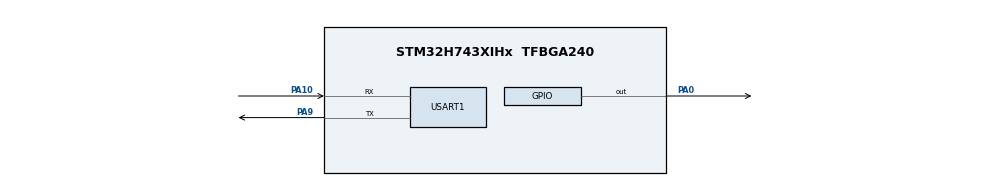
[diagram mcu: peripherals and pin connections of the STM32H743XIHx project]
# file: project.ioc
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CORTEX_M7.CPU_DCache=Enabled
CORTEX_M7.CPU_ICache=Enabled
Dma.Request0=USART1_RX
Dma.USART1_RX.0.Direction=DMA_PERIPH_TO_MEMORY
Dma.USART1_RX.0.EventEnable=DISABLE
Dma.USART1_RX.0.FIFOMode=DMA_FIFOMODE_DISABLE
Dma.USART1_RX.0.Instance=DMA1_Stream0
Dma.USART1_RX.0.MemDataAlignment=DMA_MDATAALIGN_BYTE
Dma.USART1_RX.0.MemInc=DMA_MINC_ENABLE
Dma.USART1_RX.0.Mode=DMA_CIRCULAR
Dma.USART1_RX.0.PeriphDataAlignment=DMA_PDATAALIGN_BYTE
Dma.USART1_RX.0.PeriphInc=DMA_PINC_DISABLE
Dma.USART1_RX.0.Polarity=HAL_DMAMUX_REQ_GEN_RISING
Dma.USART1_RX.0.Priority=DMA_PRIORITY_LOW
Dma.USART1_RX.0.RequestNumber=1
Dma.USART1_RX.0.SignalID=NONE
Dma.USART1_RX.0.SyncEnable=DISABLE
Dma.USART1_RX.0.SyncPolarity=HAL_DMAMUX_SYNC_NO_EVENT
Dma.USART1_RX.0.SyncRequestNumber=1
Dma.USART1_RX.0.SyncSignalID=NONE
Mcu.Family=STM32H7
Mcu.Name=STM32H743XIHx
Mcu.Package=TFBGA240
NVIC.DMA1_Stream0_IRQn=true\:0\:0\:false\:false\:true\:false\:true
NVIC.PriorityGroup=NVIC_PRIORITYGROUP_4
NVIC.USART1_IRQn=true\:0\:0\:false\:false\:true\:true\:true
PA0.Signal=GPIO_Output
PA10.Mode=Asynchronous
PA10.Signal=USART1_RX
PA13\ (JTMS/SWDIO).Mode=Serial_Wire
PA13\ (JTMS/SWDIO).Signal=DEBUG_JTMS-SWDIO
PA14\ (JTCK/SWCLK).Mode=Serial_Wire
PA14\ (JTCK/SWCLK).Signal=DEBUG_JTCK-SWCLK
PA9.Mode=Asynchronous
PA9.Signal=USART1_TX
PC14-OSC32_IN\ (OSC32_IN).Mode=LSE-External-Oscillator
PC14-OSC32_IN\ (OSC32_IN).Signal=RCC_OSC32_IN
PC15-OSC32_OUT\ (OSC32_OUT).Mode=LSE-External-Oscillator
PC15-OSC32_OUT\ (OSC32_OUT).Signal=RCC_OSC32_OUT
PH0-OSC_IN\ (PH0).Mode=HSE-External-Oscillator
PH0-OSC_IN\ (PH0).Signal=RCC_OSC_IN
PH1-OSC_OUT\ (PH1).Mode=HSE-External-Oscillator
PH1-OSC_OUT\ (PH1).Signal=RCC_OSC_OUT
ProjectManager.HeapSize=0x200
ProjectManager.StackSize=0x400
ProjectManager.TargetToolchain=MDK-ARM V5
RCC.ADCFreq_Value=400000000
RCC.APB1Freq_Value=100000000
RCC.APB2Freq_Value=100000000
RCC.APB3Freq_Value=100000000
RCC.APB4Freq_Value=100000000
RCC.CortexFreq_Value=400000000
RCC.D1PPRE=RCC_APB3_DIV2
RCC.D2PPRE1=RCC_APB1_DIV2
RCC.D2PPRE2=RCC_APB2_DIV2
RCC.D3PPRE=RCC_APB4_DIV2
RCC.DIVM1=5
RCC.DIVM2=5
RCC.DIVM3=5
RCC.DIVN1=160
RCC.DIVN2=160
RCC.DIVN3=160
RCC.HCLKFreq_Value=200000000
RCC.HPRE=RCC_HCLK_DIV2
RCC.HSE_Timout=500
RCC.PLL2FRACN=0
RCC.PLL3FRACN=0
RCC.PLLFRACN=0
RCC.PLLSourceVirtual=RCC_PLLSOURCE_HSE
RCC.SYSCLKFreq_VALUE=400000000
RCC.SYSCLKSource=RCC_SYSCLKSOURCE_PLLCLK
RCC.USBFreq_Value=400000000
USART1.VirtualMode-Asynchronous=VM_ASYNC
board=custom

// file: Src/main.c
/* USER CODE BEGIN Header */
/**
  ******************************************************************************
  * @file           : main.c
  * @brief          : Main program body
  ******************************************************************************
  * @attention
  *
  * <h2><center>&copy; Copyright (c) 2020 STMicroelectronics.
  * All rights reserved.</center></h2>
  *
  * This software component is licensed by ST under BSD 3-Clause license,
  * the "License"; You may not use this file except in compliance with the
  * License. You may obtain a copy of the License at:
  *                        opensource.org/licenses/BSD-3-Clause
  *
  ******************************************************************************
  */
/* USER CODE END Header */
#include "main.h"

/* USER CODE BEGIN Includes */
#include "shell_port.h"
#include <stdio.h>
/* USER CODE END Includes */

/* USER CODE BEGIN PM */

int fputc(int ch, FILE* stream)
{
	/* 堵塞判断串口是否发送完成 */
	while ((USART1->ISR & 0X40) == 0);

	/* 串口发送完成，将该字符发送 */
	USART1->TDR = (uint8_t)ch;

	return ch;
}
/* USER CODE END PM */

UART_HandleTypeDef huart1;
DMA_HandleTypeDef hdma_usart1_rx;

/* USER CODE BEGIN PV */
uint8_t recv_buf = 0;
/* USER CODE END PV */

void SystemClock_Config(void);
static void MX_GPIO_Init(void);
static void MX_DMA_Init(void);
static void MX_USART1_UART_Init(void);

/* USER CODE BEGIN 0 */
int test2(int i1, int i2, int i3, int i4, int i5, int i6, int i7, int i8)
{
    printf("input int: %d, %d, %d, %d, %d, %d, %d, %d\r\n", i1, i2, i3, i4, i5, i6, i7, i8);
    return 0;
}
//导出到命令列表里
SHELL_EXPORT_CMD(SHELL_CMD_PERMISSION(0)|SHELL_CMD_TYPE(SHELL_TYPE_CMD_FUNC), test2, test2, test2);

/* USER CODE END 0 */

int main(void)
{

  /* Enable I-Cache---------------------------------------------------------*/
  SCB_EnableICache();

  /* Enable D-Cache---------------------------------------------------------*/
  SCB_EnableDCache();

  /* MCU Configuration--------------------------------------------------------*/

  /* Reset of all peripherals, Initializes the Flash interface and the Systick. */
  HAL_Init();

  /* Configure the system clock */
  SystemClock_Config();

  /* Initialize all configured peripherals */
  MX_GPIO_Init();
  MX_DMA_Init();
  MX_USART1_UART_Init();
  /* USER CODE BEGIN 2 */
    HAL_UART_Receive_IT(&huart1, (uint8_t*)&recv_buf, 1);
    User_Shell_Init();
  /* USER CODE END 2 */

  /* Infinite loop */
  while (1)
  {

  }
}

void SystemClock_Config(void)
{
  RCC_OscInitTypeDef RCC_OscInitStruct = {0};
  RCC_ClkInitTypeDef RCC_ClkInitStruct = {0};
  RCC_PeriphCLKInitTypeDef PeriphClkInitStruct = {0};

  /** Supply configuration update enable
  */
  HAL_PWREx_ConfigSupply(PWR_LDO_SUPPLY);
  /** Configure the main internal regulator output voltage
  */
  __HAL_PWR_VOLTAGESCALING_CONFIG(PWR_REGULATOR_VOLTAGE_SCALE1);

  while(!__HAL_PWR_GET_FLAG(PWR_FLAG_VOSRDY)) {}
  /** Initializes the RCC Oscillators according to the specified parameters
  * in the RCC_OscInitTypeDef structure.
  */
  RCC_OscInitStruct.OscillatorType = RCC_OSCILLATORTYPE_HSE;
  RCC_OscInitStruct.HSEState = RCC_HSE_ON;
  RCC_OscInitStruct.PLL.PLLState = RCC_PLL_ON;
  RCC_OscInitStruct.PLL.PLLSource = RCC_PLLSOURCE_HSE;
  RCC_OscInitStruct.PLL.PLLM = 5;
  RCC_OscInitStruct.PLL.PLLN = 160;
  RCC_OscInitStruct.PLL.PLLP = 2;
  RCC_OscInitStruct.PLL.PLLQ = 2;
  RCC_OscInitStruct.PLL.PLLR = 2;
  RCC_OscInitStruct.PLL.PLLRGE = RCC_PLL1VCIRANGE_2;
  RCC_OscInitStruct.PLL.PLLVCOSEL = RCC_PLL1VCOWIDE;
  RCC_OscInitStruct.PLL.PLLFRACN = 0;
  if (HAL_RCC_OscConfig(&RCC_OscInitStruct) != HAL_OK)
  {
    Error_Handler();
  }
  /** Initializes the CPU, AHB and APB buses clocks
  */
  RCC_ClkInitStruct.ClockType = RCC_CLOCKTYPE_HCLK|RCC_CLOCKTYPE_SYSCLK
                              |RCC_CLOCKTYPE_PCLK1|RCC_CLOCKTYPE_PCLK2
                              |RCC_CLOCKTYPE_D3PCLK1|RCC_CLOCKTYPE_D1PCLK1;
  RCC_ClkInitStruct.SYSCLKSource = RCC_SYSCLKSOURCE_PLLCLK;
  RCC_ClkInitStruct.SYSCLKDivider = RCC_SYSCLK_DIV1;
  RCC_ClkInitStruct.AHBCLKDivider = RCC_HCLK_DIV2;
  RCC_ClkInitStruct.APB3CLKDivider = RCC_APB3_DIV2;
  RCC_ClkInitStruct.APB1CLKDivider = RCC_APB1_DIV2;
  RCC_ClkInitStruct.APB2CLKDivider = RCC_APB2_DIV2;
  RCC_ClkInitStruct.APB4CLKDivider = RCC_APB4_DIV2;

  if (HAL_RCC_ClockConfig(&RCC_ClkInitStruct, FLASH_LATENCY_2) != HAL_OK)
  {
    Error_Handler();
  }
  PeriphClkInitStruct.PeriphClockSelection = RCC_PERIPHCLK_USART1;
  PeriphClkInitStruct.Usart16ClockSelection = RCC_USART16CLKSOURCE_D2PCLK2;
  if (HAL_RCCEx_PeriphCLKConfig(&PeriphClkInitStruct) != HAL_OK)
  {
    Error_Handler();
  }
}

static void MX_USART1_UART_Init(void)
{

  huart1.Instance = USART1;
  huart1.Init.BaudRate = 115200;
  huart1.Init.WordLength = UART_WORDLENGTH_8B;
  huart1.Init.StopBits = UART_STOPBITS_1;
  huart1.Init.Parity = UART_PARITY_NONE;
  huart1.Init.Mode = UART_MODE_TX_RX;
  huart1.Init.HwFlowCtl = UART_HWCONTROL_NONE;
  huart1.Init.OverSampling = UART_OVERSAMPLING_16;
  huart1.Init.OneBitSampling = UART_ONE_BIT_SAMPLE_DISABLE;
  huart1.Init.ClockPrescaler = UART_PRESCALER_DIV1;
  huart1.AdvancedInit.AdvFeatureInit = UART_ADVFEATURE_NO_INIT;
  if (HAL_UART_Init(&huart1) != HAL_OK)
  {
    Error_Handler();
  }
  if (HAL_UARTEx_SetTxFifoThreshold(&huart1, UART_TXFIFO_THRESHOLD_1_8) != HAL_OK)
  {
    Error_Handler();
  }
  if (HAL_UARTEx_SetRxFifoThreshold(&huart1, UART_RXFIFO_THRESHOLD_1_8) != HAL_OK)
  {
    Error_Handler();
  }
  if (HAL_UARTEx_DisableFifoMode(&huart1) != HAL_OK)
  {
    Error_Handler();
  }

}

static void MX_DMA_Init(void)
{

  /* DMA controller clock enable */
  __HAL_RCC_DMA1_CLK_ENABLE();

  /* DMA interrupt init */
  /* DMA1_Stream0_IRQn interrupt configuration */
  HAL_NVIC_SetPriority(DMA1_Stream0_IRQn, 0, 0);
  HAL_NVIC_EnableIRQ(DMA1_Stream0_IRQn);

}

static void MX_GPIO_Init(void)
{
  GPIO_InitTypeDef GPIO_InitStruct = {0};

  /* GPIO Ports Clock Enable */
  __HAL_RCC_GPIOA_CLK_ENABLE();
  __HAL_RCC_GPIOC_CLK_ENABLE();
  __HAL_RCC_GPIOH_CLK_ENABLE();

  /*Configure GPIO pin Output Level */
  HAL_GPIO_WritePin(GPIOA, GPIO_PIN_0, GPIO_PIN_RESET);

  /*Configure GPIO pin : PA0 */
  GPIO_InitStruct.Pin = GPIO_PIN_0;
  GPIO_InitStruct.Mode = GPIO_MODE_OUTPUT_PP;
  GPIO_InitStruct.Pull = GPIO_NOPULL;
  GPIO_InitStruct.Speed = GPIO_SPEED_FREQ_LOW;
  HAL_GPIO_Init(GPIOA, &GPIO_InitStruct);

}

/* USER CODE BEGIN 4 */
/* USER CODE BEGIN 4 */
/* 中断回调函数 */
void HAL_UART_RxCpltCallback(UART_HandleTypeDef *huart)
{
    /* 判断是哪个串口触发的中断 */
    if(huart ->Instance == USART1)
    {
        //调用shell处理数据的接口
        shellHandler(&shell, recv_buf);
        //使能串口中断接收
        HAL_UART_Receive_IT(&huart1, (uint8_t*)&recv_buf, 1);
    }
}
/* USER CODE END 4 */

void Error_Handler(void)
{
}

/************************ (C) COPYRIGHT STMicroelectronics *****END OF FILE****/
